AUTOSAR XML (schema 4-1-3)
standard types defined: boolean, uint16, uint8
package /UAES/ASW/ApplicationDataTypes
  app type Curr_Ampr_u16: category=VALUE, sw-calibration-access=READ-WRITE, compu {phys=raw*0.1; unit A}, range raw 0..65535, unit=A
package /UAES/ASW/CompuMethods
  compu method CM_boolean: 0=FALSE, 1=TRUE
package /UAES/ASW/DataTypeMappingSets
  data type mapping set DTMS_ZCUTAdpr: data-type-map{application-data-type=Curr_Ampr_u16, implementation-data-type=uint16}
package /UAES/ASW/ImplementationDataTypes
  impl type rt_Array_boolean_29: category=ARRAY
    element rt_Array_boolean_29: array-size=29, array-size-semantics=FIXED-SIZE, implementation-data-type=boolean
  impl type rt_Array_uint16_29: category=ARRAY
    element rt_Array_uint16_29: array-size=29, array-size-semantics=FIXED-SIZE, implementation-data-type=uint16
  impl type rt_Array_uint8_29: category=ARRAY
    element rt_Array_uint8_29: array-size=29, array-size-semantics=FIXED-SIZE, implementation-data-type=uint8
package /UAES/ASW/PortInterfaces
  55 x sender receiver interface:
    ComTx_bIPDS_AMPPowerSt: invalidation-policy{data-element=ComTx_bIPDS_AMPPowerSt/Val, handle-invalid=DONT-INVALIDATE}
      data Val: sw-calibration-access=READ-ONLY, range raw 0..1, type=boolean
    ComTx_bIPDS_InverterPowerSt: invalidation-policy{data-element=ComTx_bIPDS_InverterPowerSt/Val, handle-invalid=DONT-INVALIDATE}
      data Val: sw-calibration-access=READ-ONLY, range raw 0..1, type=boolean
    ComTx_bIPDS_KL15T1PowerSt: invalidation-policy{data-element=ComTx_bIPDS_KL15T1PowerSt/Val, handle-invalid=DONT-INVALIDATE}
      data Val: sw-calibration-access=READ-ONLY, range raw 0..1, type=boolean
    ComTx_bIPDS_KL15T2PowerSt: invalidation-policy{data-element=ComTx_bIPDS_KL15T2PowerSt/Val, handle-invalid=DONT-INVALIDATE}
      data Val: sw-calibration-access=READ-ONLY, range raw 0..1, type=boolean
    ComTx_bIPDS_PASPowerSt: invalidation-policy{data-element=ComTx_bIPDS_PASPowerSt/Val, handle-invalid=DONT-INVALIDATE}
      data Val: sw-calibration-access=READ-ONLY, range raw 0..1, type=boolean
    ComTx_bIPDS_PCUPowerSt: invalidation-policy{data-element=ComTx_bIPDS_PCUPowerSt/Val, handle-invalid=DONT-INVALIDATE}
      data Val: sw-calibration-access=READ-ONLY, range raw 0..1, type=boolean
    ComTx_bIPDS_Rear12VPowerSt: invalidation-policy{data-element=ComTx_bIPDS_Rear12VPowerSt/Val, handle-invalid=DONT-INVALIDATE}
      data Val: sw-calibration-access=READ-ONLY, range raw 0..1, type=boolean
    ComTx_bIPDS_RearBlowerPowerSt: invalidation-policy{data-element=ComTx_bIPDS_RearBlowerPowerSt/Val, handle-invalid=DONT-INVALIDATE}
      data Val: sw-calibration-access=READ-ONLY, range raw 0..1, type=boolean
    ComTx_bIPDS_RearCtrlPanelPowerSt: invalidation-policy{data-element=ComTx_bIPDS_RearCtrlPanelPowerSt/Val, handle-invalid=DONT-INVALIDATE}
      data Val: sw-calibration-access=READ-ONLY, range raw 0..1, type=boolean
    ComTx_bIPDS_RearEOPPowerSt: invalidation-policy{data-element=ComTx_bIPDS_RearEOPPowerSt/Val, handle-invalid=DONT-INVALIDATE}
      data Val: sw-calibration-access=READ-ONLY, range raw 0..1, type=boolean
    ComTx_bIPDS_RearMotorPowerSt: invalidation-policy{data-element=ComTx_bIPDS_RearMotorPowerSt/Val, handle-invalid=DONT-INVALIDATE}
      data Val: sw-calibration-access=READ-ONLY, range raw 0..1, type=boolean
    ComTx_bIPDS_RearRadarPowerSt: invalidation-policy{data-element=ComTx_bIPDS_RearRadarPowerSt/Val, handle-invalid=DONT-INVALIDATE}
      data Val: sw-calibration-access=READ-ONLY, range raw 0..1, type=boolean
    ComTx_bIPDS_RLALampCtlUnitPowerSt: invalidation-policy{data-element=ComTx_bIPDS_RLALampCtlUnitPowerSt/Val, handle-invalid=DONT-INVALIDATE}
      data Val: sw-calibration-access=READ-ONLY, range raw 0..1, type=boolean
    ComTx_bIPDS_RLBLampCtlUnitPowerSt: invalidation-policy{data-element=ComTx_bIPDS_RLBLampCtlUnitPowerSt/Val, handle-invalid=DONT-INVALIDATE}
      data Val: sw-calibration-access=READ-ONLY, range raw 0..1, type=boolean
    ComTx_bIPDS_RMPowerSt: invalidation-policy{data-element=ComTx_bIPDS_RMPowerSt/Val, handle-invalid=DONT-INVALIDATE}
      data Val: sw-calibration-access=READ-ONLY, range raw 0..1, type=boolean
    ComTx_bIPDS_RRALampCtlUnitPowerSt: invalidation-policy{data-element=ComTx_bIPDS_RRALampCtlUnitPowerSt/Val, handle-invalid=DONT-INVALIDATE}
      data Val: sw-calibration-access=READ-ONLY, range raw 0..1, type=boolean
    ComTx_bIPDS_RRBLampCtlUnitPowerSt: invalidation-policy{data-element=ComTx_bIPDS_RRBLampCtlUnitPowerSt/Val, handle-invalid=DONT-INVALIDATE}
      data Val: sw-calibration-access=READ-ONLY, range raw 0..1, type=boolean
    ComTx_u16IPDS_AMPPowerCurrent: invalidation-policy{data-element=ComTx_u16IPDS_AMPPowerCurrent/Val, handle-invalid=DONT-INVALIDATE}
      data Val: sw-calibration-access=READ-ONLY, range raw 0..65535, type=uint16
    ComTx_u16IPDS_InverterPowerCurrent: invalidation-policy{data-element=ComTx_u16IPDS_InverterPowerCurrent/Val, handle-invalid=DONT-INVALIDATE}
      data Val: sw-calibration-access=READ-ONLY, range raw 0..65535, type=uint16
    ComTx_u16IPDS_KL15T1PowerCurrent: invalidation-policy{data-element=ComTx_u16IPDS_KL15T1PowerCurrent/Val, handle-invalid=DONT-INVALIDATE}
      data Val: sw-calibration-access=READ-ONLY, range raw 0..65535, type=uint16
    ComTx_u16IPDS_KL15T2PowerCurrent: invalidation-policy{data-element=ComTx_u16IPDS_KL15T2PowerCurrent/Val, handle-invalid=DONT-INVALIDATE}
      data Val: sw-calibration-access=READ-ONLY, range raw 0..65535, type=uint16
    ComTx_u16IPDS_PASPowerCurrent: invalidation-policy{data-element=ComTx_u16IPDS_PASPowerCurrent/Val, handle-invalid=DONT-INVALIDATE}
      data Val: sw-calibration-access=READ-ONLY, range raw 0..65535, type=uint16
    ComTx_u16IPDS_PCUPowerCurrent: invalidation-policy{data-element=ComTx_u16IPDS_PCUPowerCurrent/Val, handle-invalid=DONT-INVALIDATE}
      data Val: sw-calibration-access=READ-ONLY, range raw 0..65535, type=uint16
    ComTx_u16IPDS_Rear12VPowerCurrent: invalidation-policy{data-element=ComTx_u16IPDS_Rear12VPowerCurrent/Val, handle-invalid=DONT-INVALIDATE}
      data Val: sw-calibration-access=READ-ONLY, range raw 0..65535, type=uint16
    ComTx_u16IPDS_RearBlowerPowerCurrent: invalidation-policy{data-element=ComTx_u16IPDS_RearBlowerPowerCurrent/Val, handle-invalid=DONT-INVALIDATE}
      data Val: sw-calibration-access=READ-ONLY, range raw 0..65535, type=uint16
    ComTx_u16IPDS_RearCtrlPanelPowerCurrent: invalidation-policy{data-element=ComTx_u16IPDS_RearCtrlPanelPowerCurrent/Val, handle-invalid=DONT-INVALIDATE}
      data Val: sw-calibration-access=READ-ONLY, range raw 0..65535, type=uint16
    ComTx_u16IPDS_RearEOPPowerCurrent: invalidation-policy{data-element=ComTx_u16IPDS_RearEOPPowerCurrent/Val, handle-invalid=DONT-INVALIDATE}
      data Val: sw-calibration-access=READ-ONLY, range raw 0..65535, type=uint16
    ComTx_u16IPDS_RearMotorPowerCurrent: invalidation-policy{data-element=ComTx_u16IPDS_RearMotorPowerCurrent/Val, handle-invalid=DONT-INVALIDATE}
      data Val: sw-calibration-access=READ-ONLY, range raw 0..65535, type=uint16
    ComTx_u16IPDS_RearRadarPowerCurrent: invalidation-policy{data-element=ComTx_u16IPDS_RearRadarPowerCurrent/Val, handle-invalid=DONT-INVALIDATE}
      data Val: sw-calibration-access=READ-ONLY, range raw 0..65535, type=uint16
    ComTx_u16IPDS_RLALampCtlUnitPowerCurrent: invalidation-policy{data-element=ComTx_u16IPDS_RLALampCtlUnitPowerCurrent/Val, handle-invalid=DONT-INVALIDATE}
      data Val: sw-calibration-access=READ-ONLY, range raw 0..65535, type=uint16
    ComTx_u16IPDS_RLBLampCtlUnitPowerCurrent: invalidation-policy{data-element=ComTx_u16IPDS_RLBLampCtlUnitPowerCurrent/Val, handle-invalid=DONT-INVALIDATE}
      data Val: sw-calibration-access=READ-ONLY, range raw 0..65535, type=uint16
    ComTx_u16IPDS_RMPowerCurrent: invalidation-policy{data-element=ComTx_u16IPDS_RMPowerCurrent/Val, handle-invalid=DONT-INVALIDATE}
      data Val: sw-calibration-access=READ-ONLY, range raw 0..65535, type=uint16
    ComTx_u16IPDS_RRALampCtlUnitPowerCurrent: invalidation-policy{data-element=ComTx_u16IPDS_RRALampCtlUnitPowerCurrent/Val, handle-invalid=DONT-INVALIDATE}
      data Val: sw-calibration-access=READ-ONLY, range raw 0..65535, type=uint16
    ComTx_u16IPDS_RRBLampCtlUnitPowerCurrent: invalidation-policy{data-element=ComTx_u16IPDS_RRBLampCtlUnitPowerCurrent/Val, handle-invalid=DONT-INVALIDATE}
      data Val: sw-calibration-access=READ-ONLY, range raw 0..65535, type=uint16
    ComTx_u8IPDS_AMPPowerFaultSt: invalidation-policy{data-element=ComTx_u8IPDS_AMPPowerFaultSt/Val, handle-invalid=DONT-INVALIDATE}
      data Val: sw-calibration-access=READ-ONLY, range raw 0..255, type=uint8
    ComTx_u8IPDS_InverterPowerFaultSt: invalidation-policy{data-element=ComTx_u8IPDS_InverterPowerFaultSt/Val, handle-invalid=DONT-INVALIDATE}
      data Val: sw-calibration-access=READ-ONLY, range raw 0..255, type=uint8
    ComTx_u8IPDS_KL15T1PowerFaultSt: invalidation-policy{data-element=ComTx_u8IPDS_KL15T1PowerFaultSt/Val, handle-invalid=DONT-INVALIDATE}
      data Val: sw-calibration-access=READ-ONLY, range raw 0..255, type=uint8
    ComTx_u8IPDS_KL15T2PowerFaultSt: invalidation-policy{data-element=ComTx_u8IPDS_KL15T2PowerFaultSt/Val, handle-invalid=DONT-INVALIDATE}
      data Val: sw-calibration-access=READ-ONLY, range raw 0..255, type=uint8
    ComTx_u8IPDS_PASPowerFaultSt: invalidation-policy{data-element=ComTx_u8IPDS_PASPowerFaultSt/Val, handle-invalid=DONT-INVALIDATE}
      data Val: sw-calibration-access=READ-ONLY, range raw 0..255, type=uint8
    ComTx_u8IPDS_PCUPowerFaultSt: invalidation-policy{data-element=ComTx_u8IPDS_PCUPowerFaultSt/Val, handle-invalid=DONT-INVALIDATE}
      data Val: sw-calibration-access=READ-ONLY, range raw 0..255, type=uint8
    ComTx_u8IPDS_Rear12VPowerFaultSt: invalidation-policy{data-element=ComTx_u8IPDS_Rear12VPowerFaultSt/Val, handle-invalid=DONT-INVALIDATE}
      data Val: sw-calibration-access=READ-ONLY, range raw 0..255, type=uint8
    ComTx_u8IPDS_RearBlowerPowerFaultSt: invalidation-policy{data-element=ComTx_u8IPDS_RearBlowerPowerFaultSt/Val, handle-invalid=DONT-INVALIDATE}
      data Val: sw-calibration-access=READ-ONLY, range raw 0..255, type=uint8
    ComTx_u8IPDS_RearCtrlPanelPowerFaultSt: invalidation-policy{data-element=ComTx_u8IPDS_RearCtrlPanelPowerFaultSt/Val, handle-invalid=DONT-INVALIDATE}
      data Val: sw-calibration-access=READ-ONLY, range raw 0..255, type=uint8
    ComTx_u8IPDS_RearEOPPowerFaultSt: invalidation-policy{data-element=ComTx_u8IPDS_RearEOPPowerFaultSt/Val, handle-invalid=DONT-INVALIDATE}
      data Val: sw-calibration-access=READ-ONLY, range raw 0..255, type=uint8
    ComTx_u8IPDS_RearMotorPowerFaultSt: invalidation-policy{data-element=ComTx_u8IPDS_RearMotorPowerFaultSt/Val, handle-invalid=DONT-INVALIDATE}
      data Val: sw-calibration-access=READ-ONLY, range raw 0..255, type=uint8
    ComTx_u8IPDS_RearRadarPowerFaultSt: invalidation-policy{data-element=ComTx_u8IPDS_RearRadarPowerFaultSt/Val, handle-invalid=DONT-INVALIDATE}
      data Val: sw-calibration-access=READ-ONLY, range raw 0..255, type=uint8
    ComTx_u8IPDS_RLALampCtlUnitPowerFaultSt: invalidation-policy{data-element=ComTx_u8IPDS_RLALampCtlUnitPowerFaultSt/Val, handle-invalid=DONT-INVALIDATE}
      data Val: sw-calibration-access=READ-ONLY, range raw 0..255, type=uint8
    ComTx_u8IPDS_RLBLampCtlUnitPowerFaultSt: invalidation-policy{data-element=ComTx_u8IPDS_RLBLampCtlUnitPowerFaultSt/Val, handle-invalid=DONT-INVALIDATE}
      data Val: sw-calibration-access=READ-ONLY, range raw 0..255, type=uint8
    ComTx_u8IPDS_RMPowerFaultSt: invalidation-policy{data-element=ComTx_u8IPDS_RMPowerFaultSt/Val, handle-invalid=DONT-INVALIDATE}
      data Val: sw-calibration-access=READ-ONLY, range raw 0..255, type=uint8
    ComTx_u8IPDS_RRALampCtlUnitPowerFaultSt: invalidation-policy{data-element=ComTx_u8IPDS_RRALampCtlUnitPowerFaultSt/Val, handle-invalid=DONT-INVALIDATE}
      data Val: sw-calibration-access=READ-ONLY, range raw 0..255, type=uint8
    ComTx_u8IPDS_RRBLampCtlUnitPowerFaultSt: invalidation-policy{data-element=ComTx_u8IPDS_RRBLampCtlUnitPowerFaultSt/Val, handle-invalid=DONT-INVALIDATE}
      data Val: sw-calibration-access=READ-ONLY, range raw 0..255, type=uint8
    PwrSply_abPwrSt: invalidation-policy{data-element=PwrSply_abPwrSt/Val, handle-invalid=DONT-INVALIDATE}
      data Val: sw-calibration-access=READ-ONLY, range raw 0..1, type=rt_Array_boolean_29
    PwrSply_au16PwrCurr: invalidation-policy{data-element=PwrSply_au16PwrCurr/Val, handle-invalid=DONT-INVALIDATE}
      data Val: sw-calibration-access=READ-ONLY, range raw 0..65535, type=rt_Array_uint16_29
    PwrSply_au8PwrFaultSt: invalidation-policy{data-element=PwrSply_au8PwrFaultSt/Val, handle-invalid=DONT-INVALIDATE}
      data Val: sw-calibration-access=READ-ONLY, type=rt_Array_uint8_29
    PwrSply_u8VehicleTypeCfg: invalidation-policy{data-element=PwrSply_u8VehicleTypeCfg/Val, handle-invalid=DONT-INVALIDATE}
      data Val: sw-calibration-access=READ-ONLY, range raw 0..255, type=uint8
package /UAES/ASW/SwComponentTypes
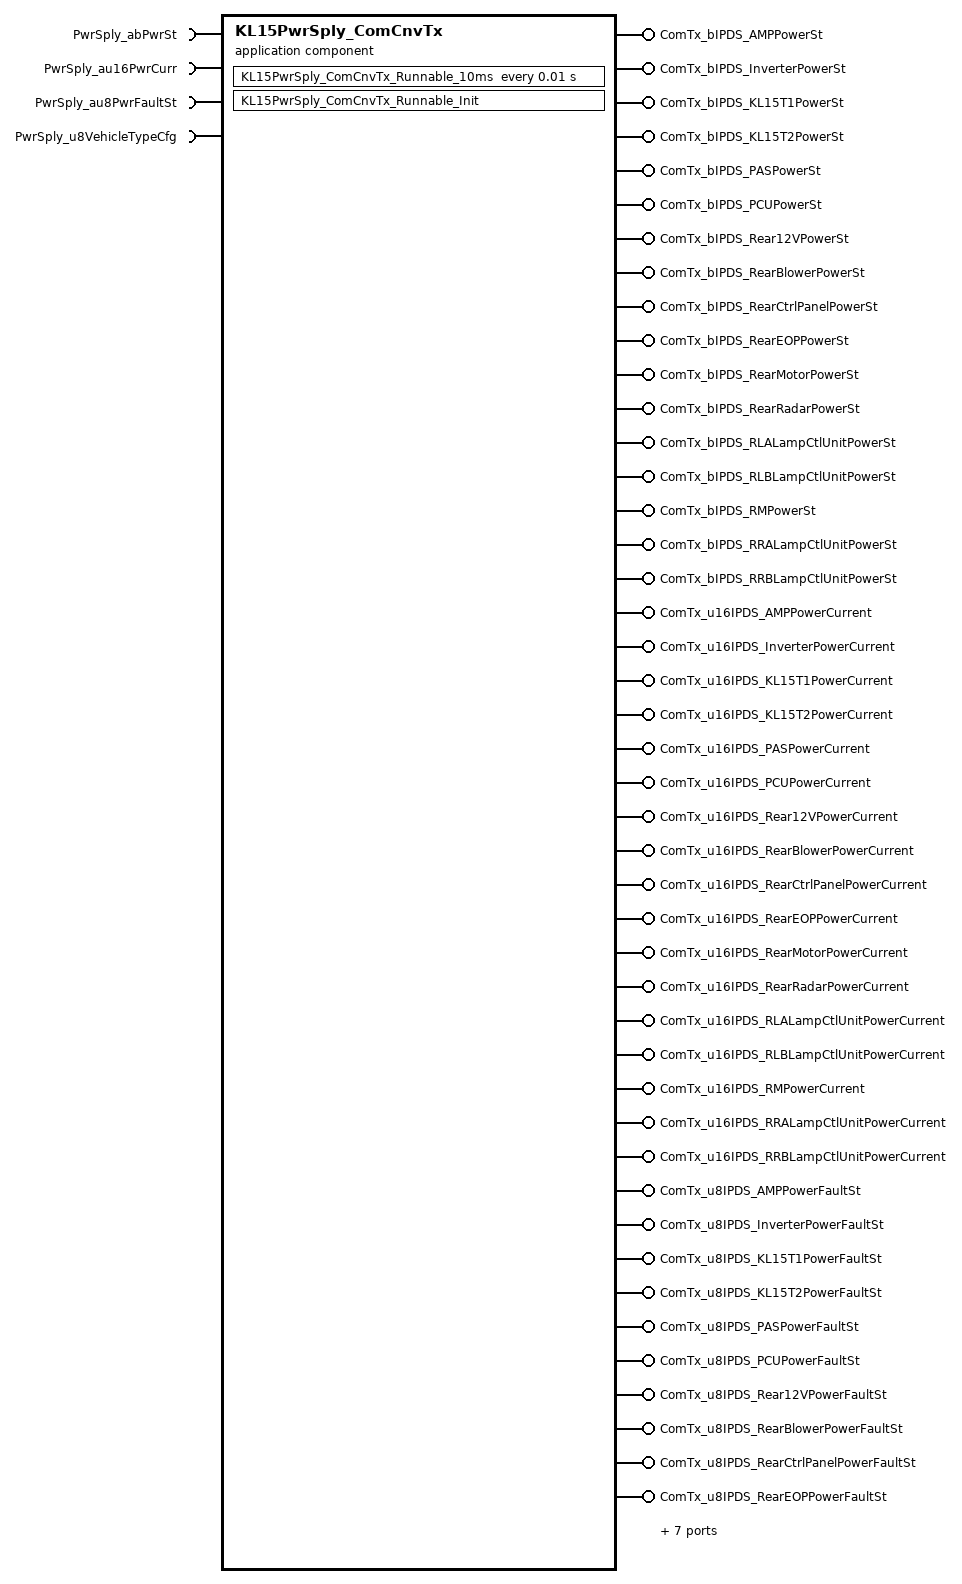
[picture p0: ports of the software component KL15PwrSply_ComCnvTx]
  application sw component type KL15PwrSply_ComCnvTx
    51 x provide port:
      ComTx_bIPDS_AMPPowerSt: nonqueued-sender-com-spec{data-element=ComTx_bIPDS_AMPPowerSt/Val, init-value=0}, provided-interface=ComTx_bIPDS_AMPPowerSt
      ComTx_bIPDS_InverterPowerSt: nonqueued-sender-com-spec{data-element=ComTx_bIPDS_InverterPowerSt/Val, init-value=0}, provided-interface=ComTx_bIPDS_InverterPowerSt
      ComTx_bIPDS_KL15T1PowerSt: nonqueued-sender-com-spec{data-element=ComTx_bIPDS_KL15T1PowerSt/Val, init-value=0}, provided-interface=ComTx_bIPDS_KL15T1PowerSt
      ComTx_bIPDS_KL15T2PowerSt: nonqueued-sender-com-spec{data-element=ComTx_bIPDS_KL15T2PowerSt/Val, init-value=0}, provided-interface=ComTx_bIPDS_KL15T2PowerSt
      ComTx_bIPDS_PASPowerSt: nonqueued-sender-com-spec{data-element=ComTx_bIPDS_PASPowerSt/Val, init-value=0}, provided-interface=ComTx_bIPDS_PASPowerSt
      ComTx_bIPDS_PCUPowerSt: nonqueued-sender-com-spec{data-element=ComTx_bIPDS_PCUPowerSt/Val, init-value=0}, provided-interface=ComTx_bIPDS_PCUPowerSt
      ComTx_bIPDS_Rear12VPowerSt: nonqueued-sender-com-spec{data-element=ComTx_bIPDS_Rear12VPowerSt/Val, init-value=0}, provided-interface=ComTx_bIPDS_Rear12VPowerSt
      ComTx_bIPDS_RearBlowerPowerSt: nonqueued-sender-com-spec{data-element=ComTx_bIPDS_RearBlowerPowerSt/Val, init-value=0}, provided-interface=ComTx_bIPDS_RearBlowerPowerSt
      ComTx_bIPDS_RearCtrlPanelPowerSt: nonqueued-sender-com-spec{data-element=ComTx_bIPDS_RearCtrlPanelPowerSt/Val, init-value=0}, provided-interface=ComTx_bIPDS_RearCtrlPanelPowerSt
      ComTx_bIPDS_RearEOPPowerSt: nonqueued-sender-com-spec{data-element=ComTx_bIPDS_RearEOPPowerSt/Val, init-value=0}, provided-interface=ComTx_bIPDS_RearEOPPowerSt
      ComTx_bIPDS_RearMotorPowerSt: nonqueued-sender-com-spec{data-element=ComTx_bIPDS_RearMotorPowerSt/Val, init-value=0}, provided-interface=ComTx_bIPDS_RearMotorPowerSt
      ComTx_bIPDS_RearRadarPowerSt: nonqueued-sender-com-spec{data-element=ComTx_bIPDS_RearRadarPowerSt/Val, init-value=0}, provided-interface=ComTx_bIPDS_RearRadarPowerSt
      ComTx_bIPDS_RLALampCtlUnitPowerSt: nonqueued-sender-com-spec{data-element=ComTx_bIPDS_RLALampCtlUnitPowerSt/Val, init-value=0}, provided-interface=ComTx_bIPDS_RLALampCtlUnitPowerSt
      ComTx_bIPDS_RLBLampCtlUnitPowerSt: nonqueued-sender-com-spec{data-element=ComTx_bIPDS_RLBLampCtlUnitPowerSt/Val, init-value=0}, provided-interface=ComTx_bIPDS_RLBLampCtlUnitPowerSt
      ComTx_bIPDS_RMPowerSt: nonqueued-sender-com-spec{data-element=ComTx_bIPDS_RMPowerSt/Val, init-value=0}, provided-interface=ComTx_bIPDS_RMPowerSt
      ComTx_bIPDS_RRALampCtlUnitPowerSt: nonqueued-sender-com-spec{data-element=ComTx_bIPDS_RRALampCtlUnitPowerSt/Val, init-value=0}, provided-interface=ComTx_bIPDS_RRALampCtlUnitPowerSt
      ComTx_bIPDS_RRBLampCtlUnitPowerSt: nonqueued-sender-com-spec{data-element=ComTx_bIPDS_RRBLampCtlUnitPowerSt/Val, init-value=0}, provided-interface=ComTx_bIPDS_RRBLampCtlUnitPowerSt
      ComTx_u16IPDS_AMPPowerCurrent: nonqueued-sender-com-spec{data-element=ComTx_u16IPDS_AMPPowerCurrent/Val, init-value=0}, provided-interface=ComTx_u16IPDS_AMPPowerCurrent
      ComTx_u16IPDS_InverterPowerCurrent: nonqueued-sender-com-spec{data-element=ComTx_u16IPDS_InverterPowerCurrent/Val, init-value=0}, provided-interface=ComTx_u16IPDS_InverterPowerCurrent
      ComTx_u16IPDS_KL15T1PowerCurrent: nonqueued-sender-com-spec{data-element=ComTx_u16IPDS_KL15T1PowerCurrent/Val, init-value=0}, provided-interface=ComTx_u16IPDS_KL15T1PowerCurrent
      ComTx_u16IPDS_KL15T2PowerCurrent: nonqueued-sender-com-spec{data-element=ComTx_u16IPDS_KL15T2PowerCurrent/Val, init-value=0}, provided-interface=ComTx_u16IPDS_KL15T2PowerCurrent
      ComTx_u16IPDS_PASPowerCurrent: nonqueued-sender-com-spec{data-element=ComTx_u16IPDS_PASPowerCurrent/Val, init-value=0}, provided-interface=ComTx_u16IPDS_PASPowerCurrent
      ComTx_u16IPDS_PCUPowerCurrent: nonqueued-sender-com-spec{data-element=ComTx_u16IPDS_PCUPowerCurrent/Val, init-value=0}, provided-interface=ComTx_u16IPDS_PCUPowerCurrent
      ComTx_u16IPDS_Rear12VPowerCurrent: nonqueued-sender-com-spec{data-element=ComTx_u16IPDS_Rear12VPowerCurrent/Val, init-value=0}, provided-interface=ComTx_u16IPDS_Rear12VPowerCurrent
      ComTx_u16IPDS_RearBlowerPowerCurrent: nonqueued-sender-com-spec{data-element=ComTx_u16IPDS_RearBlowerPowerCurrent/Val, init-value=0}, provided-interface=ComTx_u16IPDS_RearBlowerPowerCurrent
      ComTx_u16IPDS_RearCtrlPanelPowerCurrent: nonqueued-sender-com-spec{data-element=ComTx_u16IPDS_RearCtrlPanelPowerCurrent/Val, init-value=0}, provided-interface=ComTx_u16IPDS_RearCtrlPanelPowerCurrent
      ComTx_u16IPDS_RearEOPPowerCurrent: nonqueued-sender-com-spec{data-element=ComTx_u16IPDS_RearEOPPowerCurrent/Val, init-value=0}, provided-interface=ComTx_u16IPDS_RearEOPPowerCurrent
      ComTx_u16IPDS_RearMotorPowerCurrent: nonqueued-sender-com-spec{data-element=ComTx_u16IPDS_RearMotorPowerCurrent/Val, init-value=0}, provided-interface=ComTx_u16IPDS_RearMotorPowerCurrent
      ComTx_u16IPDS_RearRadarPowerCurrent: nonqueued-sender-com-spec{data-element=ComTx_u16IPDS_RearRadarPowerCurrent/Val, init-value=0}, provided-interface=ComTx_u16IPDS_RearRadarPowerCurrent
      ComTx_u16IPDS_RLALampCtlUnitPowerCurrent: nonqueued-sender-com-spec{data-element=ComTx_u16IPDS_RLALampCtlUnitPowerCurrent/Val, init-value=0}, provided-interface=ComTx_u16IPDS_RLALampCtlUnitPowerCurrent
      ComTx_u16IPDS_RLBLampCtlUnitPowerCurrent: nonqueued-sender-com-spec{data-element=ComTx_u16IPDS_RLBLampCtlUnitPowerCurrent/Val, init-value=0}, provided-interface=ComTx_u16IPDS_RLBLampCtlUnitPowerCurrent
      ComTx_u16IPDS_RMPowerCurrent: nonqueued-sender-com-spec{data-element=ComTx_u16IPDS_RMPowerCurrent/Val, init-value=0}, provided-interface=ComTx_u16IPDS_RMPowerCurrent
      ComTx_u16IPDS_RRALampCtlUnitPowerCurrent: nonqueued-sender-com-spec{data-element=ComTx_u16IPDS_RRALampCtlUnitPowerCurrent/Val, init-value=0}, provided-interface=ComTx_u16IPDS_RRALampCtlUnitPowerCurrent
      ComTx_u16IPDS_RRBLampCtlUnitPowerCurrent: nonqueued-sender-com-spec{data-element=ComTx_u16IPDS_RRBLampCtlUnitPowerCurrent/Val, init-value=0}, provided-interface=ComTx_u16IPDS_RRBLampCtlUnitPowerCurrent
      ComTx_u8IPDS_AMPPowerFaultSt: nonqueued-sender-com-spec{data-element=ComTx_u8IPDS_AMPPowerFaultSt/Val, init-value=0}, provided-interface=ComTx_u8IPDS_AMPPowerFaultSt
      ComTx_u8IPDS_InverterPowerFaultSt: nonqueued-sender-com-spec{data-element=ComTx_u8IPDS_InverterPowerFaultSt/Val, init-value=0}, provided-interface=ComTx_u8IPDS_InverterPowerFaultSt
      ComTx_u8IPDS_KL15T1PowerFaultSt: nonqueued-sender-com-spec{data-element=ComTx_u8IPDS_KL15T1PowerFaultSt/Val, init-value=0}, provided-interface=ComTx_u8IPDS_KL15T1PowerFaultSt
      ComTx_u8IPDS_KL15T2PowerFaultSt: nonqueued-sender-com-spec{data-element=ComTx_u8IPDS_KL15T2PowerFaultSt/Val, init-value=0}, provided-interface=ComTx_u8IPDS_KL15T2PowerFaultSt
      ComTx_u8IPDS_PASPowerFaultSt: nonqueued-sender-com-spec{data-element=ComTx_u8IPDS_PASPowerFaultSt/Val, init-value=0}, provided-interface=ComTx_u8IPDS_PASPowerFaultSt
      ComTx_u8IPDS_PCUPowerFaultSt: nonqueued-sender-com-spec{data-element=ComTx_u8IPDS_PCUPowerFaultSt/Val, init-value=0}, provided-interface=ComTx_u8IPDS_PCUPowerFaultSt
      ComTx_u8IPDS_Rear12VPowerFaultSt: nonqueued-sender-com-spec{data-element=ComTx_u8IPDS_Rear12VPowerFaultSt/Val, init-value=0}, provided-interface=ComTx_u8IPDS_Rear12VPowerFaultSt
      ComTx_u8IPDS_RearBlowerPowerFaultSt: nonqueued-sender-com-spec{data-element=ComTx_u8IPDS_RearBlowerPowerFaultSt/Val, init-value=0}, provided-interface=ComTx_u8IPDS_RearBlowerPowerFaultSt
      ComTx_u8IPDS_RearCtrlPanelPowerFaultSt: nonqueued-sender-com-spec{data-element=ComTx_u8IPDS_RearCtrlPanelPowerFaultSt/Val, init-value=0}, provided-interface=ComTx_u8IPDS_RearCtrlPanelPowerFaultSt
      ComTx_u8IPDS_RearEOPPowerFaultSt: nonqueued-sender-com-spec{data-element=ComTx_u8IPDS_RearEOPPowerFaultSt/Val, init-value=0}, provided-interface=ComTx_u8IPDS_RearEOPPowerFaultSt
      ComTx_u8IPDS_RearMotorPowerFaultSt: nonqueued-sender-com-spec{data-element=ComTx_u8IPDS_RearMotorPowerFaultSt/Val, init-value=0}, provided-interface=ComTx_u8IPDS_RearMotorPowerFaultSt
      ComTx_u8IPDS_RearRadarPowerFaultSt: nonqueued-sender-com-spec{data-element=ComTx_u8IPDS_RearRadarPowerFaultSt/Val, init-value=0}, provided-interface=ComTx_u8IPDS_RearRadarPowerFaultSt
      ComTx_u8IPDS_RLALampCtlUnitPowerFaultSt: nonqueued-sender-com-spec{data-element=ComTx_u8IPDS_RLALampCtlUnitPowerFaultSt/Val, init-value=0}, provided-interface=ComTx_u8IPDS_RLALampCtlUnitPowerFaultSt
      ComTx_u8IPDS_RLBLampCtlUnitPowerFaultSt: nonqueued-sender-com-spec{data-element=ComTx_u8IPDS_RLBLampCtlUnitPowerFaultSt/Val, init-value=0}, provided-interface=ComTx_u8IPDS_RLBLampCtlUnitPowerFaultSt
      ComTx_u8IPDS_RMPowerFaultSt: nonqueued-sender-com-spec{data-element=ComTx_u8IPDS_RMPowerFaultSt/Val, init-value=0}, provided-interface=ComTx_u8IPDS_RMPowerFaultSt
      ComTx_u8IPDS_RRALampCtlUnitPowerFaultSt: nonqueued-sender-com-spec{data-element=ComTx_u8IPDS_RRALampCtlUnitPowerFaultSt/Val, init-value=0}, provided-interface=ComTx_u8IPDS_RRALampCtlUnitPowerFaultSt
      ComTx_u8IPDS_RRBLampCtlUnitPowerFaultSt: nonqueued-sender-com-spec{data-element=ComTx_u8IPDS_RRBLampCtlUnitPowerFaultSt/Val, init-value=0}, provided-interface=ComTx_u8IPDS_RRBLampCtlUnitPowerFaultSt
    4 x require port:
      PwrSply_abPwrSt: nonqueued-receiver-com-spec{data-element=PwrSply_abPwrSt/Val, filter=data-filter-type=ALWAYS, init-value=29 x 0}, required-interface=PwrSply_abPwrSt
      PwrSply_au16PwrCurr: nonqueued-receiver-com-spec{data-element=PwrSply_au16PwrCurr/Val, filter=data-filter-type=ALWAYS, init-value=29 x 0}, required-interface=PwrSply_au16PwrCurr
      PwrSply_au8PwrFaultSt: nonqueued-receiver-com-spec{data-element=PwrSply_au8PwrFaultSt/Val, filter=data-filter-type=ALWAYS, init-value=29 x 0}, required-interface=PwrSply_au8PwrFaultSt
      PwrSply_u8VehicleTypeCfg: nonqueued-receiver-com-spec{data-element=PwrSply_u8VehicleTypeCfg/Val, filter=data-filter-type=ALWAYS, init-value=0}, required-interface=PwrSply_u8VehicleTypeCfg
    behavior KL15PwrSply_ComCnvTx_InternalBehavior: data-type-mapping=DTMS_ZCUTAdpr
      timing event TMT_KL15PwrSply_ComCnvTx_Runnable_10ms: start-on-event=KL15PwrSply_ComCnvTx_Runnable_10ms, period=0.01
      init event KL15PwrSply_ComCnvTx_Runnable_InitEvent: start-on-event=KL15PwrSply_ComCnvTx_Runnable_Init
      runnable KL15PwrSply_ComCnvTx_Runnable_10ms
        data-read-access:
          4 x access:
            READ_PwrSply_abPwrSt_Val: accessed-variable=PwrSply_abPwrSt.Val
            READ_PwrSply_au16PwrCurr_Val: accessed-variable=PwrSply_au16PwrCurr.Val
            READ_PwrSply_au8PwrFaultSt_Val: accessed-variable=PwrSply_au8PwrFaultSt.Val
            READ_PwrSply_u8VehicleTypeCfg_Val: accessed-variable=PwrSply_u8VehicleTypeCfg.Val
        data-write-access:
          51 x access:
            WRITE_gHSDPwrSply_bAMPPowerSt_Val: accessed-variable=ComTx_bIPDS_AMPPowerSt.Val
            WRITE_gHSDPwrSply_bInverterPowerSt_Val: accessed-variable=ComTx_bIPDS_InverterPowerSt.Val
            WRITE_gHSDPwrSply_bKL15T1PowerSt_Val: accessed-variable=ComTx_bIPDS_KL15T1PowerSt.Val
            WRITE_gHSDPwrSply_bKL15T2PowerSt_Val: accessed-variable=ComTx_bIPDS_KL15T2PowerSt.Val
            WRITE_gHSDPwrSply_bPASPowerSt_Val: accessed-variable=ComTx_bIPDS_PASPowerSt.Val
            WRITE_gHSDPwrSply_bPCUPowerSt_Val: accessed-variable=ComTx_bIPDS_PCUPowerSt.Val
            WRITE_gHSDPwrSply_bRear12VPowerSt_Val: accessed-variable=ComTx_bIPDS_Rear12VPowerSt.Val
            WRITE_gHSDPwrSply_bRearBlowerPowerSt_Val: accessed-variable=ComTx_bIPDS_RearBlowerPowerSt.Val
            WRITE_gHSDPwrSply_bRearCtrlPanelPowerSt_Val: accessed-variable=ComTx_bIPDS_RearCtrlPanelPowerSt.Val
            WRITE_gHSDPwrSply_bRearEOPPowerSt_Val: accessed-variable=ComTx_bIPDS_RearEOPPowerSt.Val
            WRITE_gHSDPwrSply_bRearMotorPowerSt_Val: accessed-variable=ComTx_bIPDS_RearMotorPowerSt.Val
            WRITE_gHSDPwrSply_bRearRadarPowerSt_Val: accessed-variable=ComTx_bIPDS_RearRadarPowerSt.Val
            WRITE_gHSDPwrSply_bRLALampCtlUnitPowerSt_Val: accessed-variable=ComTx_bIPDS_RLALampCtlUnitPowerSt.Val
            WRITE_gHSDPwrSply_bRLBLampCtlUnitPowerSt_Val: accessed-variable=ComTx_bIPDS_RLBLampCtlUnitPowerSt.Val
            WRITE_gHSDPwrSply_bRMPowerSt_Val: accessed-variable=ComTx_bIPDS_RMPowerSt.Val
            WRITE_gHSDPwrSply_bRRALampCtlUnitPowerSt_Val: accessed-variable=ComTx_bIPDS_RRALampCtlUnitPowerSt.Val
            WRITE_gHSDPwrSply_bRRBLampCtlUnitPowerSt_Val: accessed-variable=ComTx_bIPDS_RRBLampCtlUnitPowerSt.Val
            WRITE_gHSDPwrSply_u16AMPPowerCurr_Val: accessed-variable=ComTx_u16IPDS_AMPPowerCurrent.Val
            WRITE_gHSDPwrSply_u16InverterPowerCurr_Val: accessed-variable=ComTx_u16IPDS_InverterPowerCurrent.Val
            WRITE_gHSDPwrSply_u16KL15T1PowerCurr_Val: accessed-variable=ComTx_u16IPDS_KL15T1PowerCurrent.Val
            WRITE_gHSDPwrSply_u16KL15T2PowerCurr_Val: accessed-variable=ComTx_u16IPDS_KL15T2PowerCurrent.Val
            WRITE_gHSDPwrSply_u16PASPowerCurr_Val: accessed-variable=ComTx_u16IPDS_PASPowerCurrent.Val
            WRITE_gHSDPwrSply_u16PCUPowerCurr_Val: accessed-variable=ComTx_u16IPDS_PCUPowerCurrent.Val
            WRITE_gHSDPwrSply_u16Rear12VPowerCurr_Val: accessed-variable=ComTx_u16IPDS_Rear12VPowerCurrent.Val
            WRITE_gHSDPwrSply_u16RearBlowerPowerCurr_Val: accessed-variable=ComTx_u16IPDS_RearBlowerPowerCurrent.Val
            WRITE_gHSDPwrSply_u16RearCtrlPanelPowerCurr_Val: accessed-variable=ComTx_u16IPDS_RearCtrlPanelPowerCurrent.Val
            WRITE_gHSDPwrSply_u16RearEOPPowerCurr_Val: accessed-variable=ComTx_u16IPDS_RearEOPPowerCurrent.Val
            WRITE_gHSDPwrSply_u16RearMotorPowerCurr_Val: accessed-variable=ComTx_u16IPDS_RearMotorPowerCurrent.Val
            WRITE_gHSDPwrSply_u16RearRadarPowerCurr_Val: accessed-variable=ComTx_u16IPDS_RearRadarPowerCurrent.Val
            WRITE_gHSDPwrSply_u16RLALampCtlUnitPowerCurr_Val: accessed-variable=ComTx_u16IPDS_RLALampCtlUnitPowerCurrent.Val
            WRITE_gHSDPwrSply_u16RLBLampCtlUnitPowerCurr_Val: accessed-variable=ComTx_u16IPDS_RLBLampCtlUnitPowerCurrent.Val
            WRITE_gHSDPwrSply_u16RMPowerCurr_Val: accessed-variable=ComTx_u16IPDS_RMPowerCurrent.Val
            WRITE_gHSDPwrSply_u16RRALampCtlUnitPowerCurr_Val: accessed-variable=ComTx_u16IPDS_RRALampCtlUnitPowerCurrent.Val
            WRITE_gHSDPwrSply_u16RRBLampCtlUnitPowerCurr_Val: accessed-variable=ComTx_u16IPDS_RRBLampCtlUnitPowerCurrent.Val
            WRITE_gHSDPwrSply_u8AMPPowerFaultSt_Val: accessed-variable=ComTx_u8IPDS_AMPPowerFaultSt.Val
            WRITE_gHSDPwrSply_u8InverterPowerFaultSt_Val: accessed-variable=ComTx_u8IPDS_InverterPowerFaultSt.Val
            WRITE_gHSDPwrSply_u8KL15T1PowerFaultSt_Val: accessed-variable=ComTx_u8IPDS_KL15T1PowerFaultSt.Val
            WRITE_gHSDPwrSply_u8KL15T2PowerFaultSt_Val: accessed-variable=ComTx_u8IPDS_KL15T2PowerFaultSt.Val
            WRITE_gHSDPwrSply_u8PASPowerFaultSt_Val: accessed-variable=ComTx_u8IPDS_PASPowerFaultSt.Val
            WRITE_gHSDPwrSply_u8PCUPowerFaultSt_Val: accessed-variable=ComTx_u8IPDS_PCUPowerFaultSt.Val
            WRITE_gHSDPwrSply_u8Rear12VPowerFaultSt_Val: accessed-variable=ComTx_u8IPDS_Rear12VPowerFaultSt.Val
            WRITE_gHSDPwrSply_u8RearBlowerPowerFaultSt_Val: accessed-variable=ComTx_u8IPDS_RearBlowerPowerFaultSt.Val
            WRITE_gHSDPwrSply_u8RearCtrlPanelPowerFaultSt_Val: accessed-variable=ComTx_u8IPDS_RearCtrlPanelPowerFaultSt.Val
            WRITE_gHSDPwrSply_u8RearEOPPowerFaultSt_Val: accessed-variable=ComTx_u8IPDS_RearEOPPowerFaultSt.Val
            WRITE_gHSDPwrSply_u8RearMotorPowerFaultSt_Val: accessed-variable=ComTx_u8IPDS_RearMotorPowerFaultSt.Val
            WRITE_gHSDPwrSply_u8RearRadarPowerFaultSt_Val: accessed-variable=ComTx_u8IPDS_RearRadarPowerFaultSt.Val
            WRITE_gHSDPwrSply_u8RLALampCtlUnitPowerFaultSt_Val: accessed-variable=ComTx_u8IPDS_RLALampCtlUnitPowerFaultSt.Val
            WRITE_gHSDPwrSply_u8RLBLampCtlUnitPowerFaultSt_Val: accessed-variable=ComTx_u8IPDS_RLBLampCtlUnitPowerFaultSt.Val
            WRITE_gHSDPwrSply_u8RMPowerFaultSt_Val: accessed-variable=ComTx_u8IPDS_RMPowerFaultSt.Val
            WRITE_gHSDPwrSply_u8RRALampCtlUnitPowerFaultSt_Val: accessed-variable=ComTx_u8IPDS_RRALampCtlUnitPowerFaultSt.Val
            WRITE_gHSDPwrSply_u8RRBLampCtlUnitPowerFaultSt_Val: accessed-variable=ComTx_u8IPDS_RRBLampCtlUnitPowerFaultSt.Val
      runnable KL15PwrSply_ComCnvTx_Runnable_Init
        data-write-access:
          51 x access:
            WRITE_gHSDPwrSply_bAMPPowerSt_Val: accessed-variable=ComTx_bIPDS_AMPPowerSt.Val
            WRITE_gHSDPwrSply_bInverterPowerSt_Val: accessed-variable=ComTx_bIPDS_InverterPowerSt.Val
            WRITE_gHSDPwrSply_bKL15T1PowerSt_Val: accessed-variable=ComTx_bIPDS_KL15T1PowerSt.Val
            WRITE_gHSDPwrSply_bKL15T2PowerSt_Val: accessed-variable=ComTx_bIPDS_KL15T2PowerSt.Val
            WRITE_gHSDPwrSply_bPASPowerSt_Val: accessed-variable=ComTx_bIPDS_PASPowerSt.Val
            WRITE_gHSDPwrSply_bPCUPowerSt_Val: accessed-variable=ComTx_bIPDS_PCUPowerSt.Val
            WRITE_gHSDPwrSply_bRear12VPowerSt_Val: accessed-variable=ComTx_bIPDS_Rear12VPowerSt.Val
            WRITE_gHSDPwrSply_bRearBlowerPowerSt_Val: accessed-variable=ComTx_bIPDS_RearBlowerPowerSt.Val
            WRITE_gHSDPwrSply_bRearCtrlPanelPowerSt_Val: accessed-variable=ComTx_bIPDS_RearCtrlPanelPowerSt.Val
            WRITE_gHSDPwrSply_bRearEOPPowerSt_Val: accessed-variable=ComTx_bIPDS_RearEOPPowerSt.Val
            WRITE_gHSDPwrSply_bRearMotorPowerSt_Val: accessed-variable=ComTx_bIPDS_RearMotorPowerSt.Val
            WRITE_gHSDPwrSply_bRearRadarPowerSt_Val: accessed-variable=ComTx_bIPDS_RearRadarPowerSt.Val
            WRITE_gHSDPwrSply_bRLALampCtlUnitPowerSt_Val: accessed-variable=ComTx_bIPDS_RLALampCtlUnitPowerSt.Val
            WRITE_gHSDPwrSply_bRLBLampCtlUnitPowerSt_Val: accessed-variable=ComTx_bIPDS_RLBLampCtlUnitPowerSt.Val
            WRITE_gHSDPwrSply_bRMPowerSt_Val: accessed-variable=ComTx_bIPDS_RMPowerSt.Val
            WRITE_gHSDPwrSply_bRRALampCtlUnitPowerSt_Val: accessed-variable=ComTx_bIPDS_RRALampCtlUnitPowerSt.Val
            WRITE_gHSDPwrSply_bRRBLampCtlUnitPowerSt_Val: accessed-variable=ComTx_bIPDS_RRBLampCtlUnitPowerSt.Val
            WRITE_gHSDPwrSply_u16AMPPowerCurr_Val: accessed-variable=ComTx_u16IPDS_AMPPowerCurrent.Val
            WRITE_gHSDPwrSply_u16InverterPowerCurr_Val: accessed-variable=ComTx_u16IPDS_InverterPowerCurrent.Val
            WRITE_gHSDPwrSply_u16KL15T1PowerCurr_Val: accessed-variable=ComTx_u16IPDS_KL15T1PowerCurrent.Val
            WRITE_gHSDPwrSply_u16KL15T2PowerCurr_Val: accessed-variable=ComTx_u16IPDS_KL15T2PowerCurrent.Val
            WRITE_gHSDPwrSply_u16PASPowerCurr_Val: accessed-variable=ComTx_u16IPDS_PASPowerCurrent.Val
            WRITE_gHSDPwrSply_u16PCUPowerCurr_Val: accessed-variable=ComTx_u16IPDS_PCUPowerCurrent.Val
            WRITE_gHSDPwrSply_u16Rear12VPowerCurr_Val: accessed-variable=ComTx_u16IPDS_Rear12VPowerCurrent.Val
            WRITE_gHSDPwrSply_u16RearBlowerPowerCurr_Val: accessed-variable=ComTx_u16IPDS_RearBlowerPowerCurrent.Val
            WRITE_gHSDPwrSply_u16RearCtrlPanelPowerCurr_Val: accessed-variable=ComTx_u16IPDS_RearCtrlPanelPowerCurrent.Val
            WRITE_gHSDPwrSply_u16RearEOPPowerCurr_Val: accessed-variable=ComTx_u16IPDS_RearEOPPowerCurrent.Val
            WRITE_gHSDPwrSply_u16RearMotorPowerCurr_Val: accessed-variable=ComTx_u16IPDS_RearMotorPowerCurrent.Val
            WRITE_gHSDPwrSply_u16RearRadarPowerCurr_Val: accessed-variable=ComTx_u16IPDS_RearRadarPowerCurrent.Val
            WRITE_gHSDPwrSply_u16RLALampCtlUnitPowerCurr_Val: accessed-variable=ComTx_u16IPDS_RLALampCtlUnitPowerCurrent.Val
            WRITE_gHSDPwrSply_u16RLBLampCtlUnitPowerCurr_Val: accessed-variable=ComTx_u16IPDS_RLBLampCtlUnitPowerCurrent.Val
            WRITE_gHSDPwrSply_u16RMPowerCurr_Val: accessed-variable=ComTx_u16IPDS_RMPowerCurrent.Val
            WRITE_gHSDPwrSply_u16RRALampCtlUnitPowerCurr_Val: accessed-variable=ComTx_u16IPDS_RRALampCtlUnitPowerCurrent.Val
            WRITE_gHSDPwrSply_u16RRBLampCtlUnitPowerCurr_Val: accessed-variable=ComTx_u16IPDS_RRBLampCtlUnitPowerCurrent.Val
            WRITE_gHSDPwrSply_u8AMPPowerFaultSt_Val: accessed-variable=ComTx_u8IPDS_AMPPowerFaultSt.Val
            WRITE_gHSDPwrSply_u8InverterPowerFaultSt_Val: accessed-variable=ComTx_u8IPDS_InverterPowerFaultSt.Val
            WRITE_gHSDPwrSply_u8KL15T1PowerFaultSt_Val: accessed-variable=ComTx_u8IPDS_KL15T1PowerFaultSt.Val
            WRITE_gHSDPwrSply_u8KL15T2PowerFaultSt_Val: accessed-variable=ComTx_u8IPDS_KL15T2PowerFaultSt.Val
            WRITE_gHSDPwrSply_u8PASPowerFaultSt_Val: accessed-variable=ComTx_u8IPDS_PASPowerFaultSt.Val
            WRITE_gHSDPwrSply_u8PCUPowerFaultSt_Val: accessed-variable=ComTx_u8IPDS_PCUPowerFaultSt.Val
            WRITE_gHSDPwrSply_u8Rear12VPowerFaultSt_Val: accessed-variable=ComTx_u8IPDS_Rear12VPowerFaultSt.Val
            WRITE_gHSDPwrSply_u8RearBlowerPowerFaultSt_Val: accessed-variable=ComTx_u8IPDS_RearBlowerPowerFaultSt.Val
            WRITE_gHSDPwrSply_u8RearCtrlPanelPowerFaultSt_Val: accessed-variable=ComTx_u8IPDS_RearCtrlPanelPowerFaultSt.Val
            WRITE_gHSDPwrSply_u8RearEOPPowerFaultSt_Val: accessed-variable=ComTx_u8IPDS_RearEOPPowerFaultSt.Val
            WRITE_gHSDPwrSply_u8RearMotorPowerFaultSt_Val: accessed-variable=ComTx_u8IPDS_RearMotorPowerFaultSt.Val
            WRITE_gHSDPwrSply_u8RearRadarPowerFaultSt_Val: accessed-variable=ComTx_u8IPDS_RearRadarPowerFaultSt.Val
            WRITE_gHSDPwrSply_u8RLALampCtlUnitPowerFaultSt_Val: accessed-variable=ComTx_u8IPDS_RLALampCtlUnitPowerFaultSt.Val
            WRITE_gHSDPwrSply_u8RLBLampCtlUnitPowerFaultSt_Val: accessed-variable=ComTx_u8IPDS_RLBLampCtlUnitPowerFaultSt.Val
            WRITE_gHSDPwrSply_u8RMPowerFaultSt_Val: accessed-variable=ComTx_u8IPDS_RMPowerFaultSt.Val
            WRITE_gHSDPwrSply_u8RRALampCtlUnitPowerFaultSt_Val: accessed-variable=ComTx_u8IPDS_RRALampCtlUnitPowerFaultSt.Val
            WRITE_gHSDPwrSply_u8RRBLampCtlUnitPowerFaultSt_Val: accessed-variable=ComTx_u8IPDS_RRBLampCtlUnitPowerFaultSt.Val
  swc implementation KL15PwrSply_ComCnvTx_Implementation: behavior=KL15PwrSply_ComCnvTx_InternalBehavior
    code-descriptors:
      code Default: artifact-descriptors=autosar-engineering-object={short-label=Default, category=SWSRC}
package /UAES/ASW/Units
  unit Curr_A: display-name=A, factor-si-to-unit=1, offset-si-to-unit=0
  unit NoUnit: factor-si-to-unit=1, offset-si-to-unit=0
